# AT32UC3L0256 device description
Architecture: AVR32_UC3; Family: AVR UC3
Registers are 32-bit, read-write, reset 0x0 unless marked. A register's access mark holds for its fields unless they carry their own. Offsets are from the block's base; [hi:lo] are bit positions; lines under a group give offsets from that group; {n}, {i} and the like mark numbered series; 'fields as' and 'values as' point back to an identical list.

## TWIS — Two-wire Slave Interface
Instances: TWIS0 0xffff4c00, TWIS1 0xffff5000
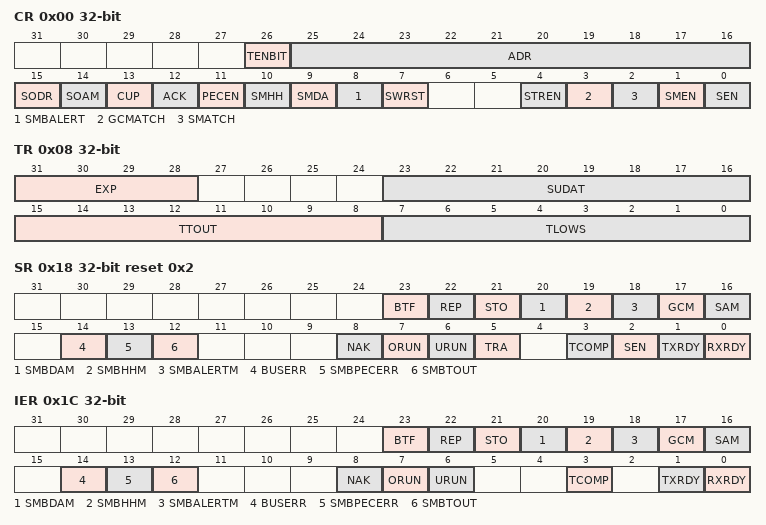
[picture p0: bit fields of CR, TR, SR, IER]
0x00 CR — Control Register
  [26] TENBIT — Ten Bit Address Match
  [25:16] ADR — Slave Address
  [15] SODR — Stretch Clock on Data Byte Reception
  [14] SOAM — Stretch Clock on Address Match
  [13] CUP — NBYTES Count Up
  [12] ACK — Slave Receiver Data Phase ACK Value
  [11] PECEN — Packet Error Checking Enable
  [10] SMHH — SMBus Host Header
  [9] SMDA — SMBus Default Address
  [8] SMBALERT — SMBus Alert
  [7] SWRST — Software Reset
  [4] STREN — Clock Stretch Enable
  [3] GCMATCH — General Call Address Match
  [2] SMATCH — Slave Address Match
  [1] SMEN — SMBus Mode Enable
  [0] SEN — Slave Enable
0x04 NBYTES
  [7:0] NBYTES — Number of Bytes to Transfer
0x08 TR — Timing Register
  [31:28] EXP — Clock Prescaler
  [23:16] SUDAT — Data Setup Cycles
  [15:8] TTOUT — SMBus Ttimeout Cycles
  [7:0] TLOWS — SMBus Tlow:sext Cycles
0x0C RHR ro — Receive Holding Register
  [7:0] RXDATA — Received Data Byte
0x10 THR wo — Transmit Holding Register
  [7:0] TXDATA — Data Byte to Transmit
0x14 PECR ro — Packet Error Check Register
  [7:0] PEC — Calculated PEC Value
0x18 SR ro reset 0x2 — Status Register
  [23] BTF — Byte Transfer Finished
  [22] REP — Repeated Start Received
  [21] STO — Stop Received
  [20] SMBDAM — SMBus Default Address Match
  [19] SMBHHM — SMBus Host Header Address Match
  [18] SMBALERTM — SMBus Alert Response Address Match
  [17] GCM — General Call Match
  [16] SAM — Slave Address Match
  [14] BUSERR — Bus Error
  [13] SMBPECERR — SMBus PEC Error
  [12] SMBTOUT — SMBus Timeout
  [8] NAK — NAK Received
  [7] ORUN — Overrun
  [6] URUN — Underrun
  [5] TRA — Transmitter Mode
  [3] TCOMP — Transmission Complete
  [2] SEN — Slave Enabled
  [1] TXRDY — TX Buffer Ready
  [0] RXRDY — RX Buffer Ready
0x1C IER wo — Interrupt Enable Register
  [23] BTF — Byte Transfer Finished
  [22] REP — Repeated Start Received
  [21] STO — Stop Received
  [20] SMBDAM — SMBus Default Address Match
  [19] SMBHHM — SMBus Host Header Address Match
  [18] SMBALERTM — SMBus Alert Response Address Match
  [17] GCM — General Call Match
  [16] SAM — Slave Address Match
  [14] BUSERR — Bus Error
  [13] SMBPECERR — SMBus PEC Error
  [12] SMBTOUT — SMBus Timeout
  [8] NAK — NAK Received
  [7] ORUN — Overrun
  [6] URUN — Underrun
  [3] TCOMP — Transmission Complete
  [1] TXRDY — TX Buffer Ready
  [0] RXRDY — RX Buffer Ready
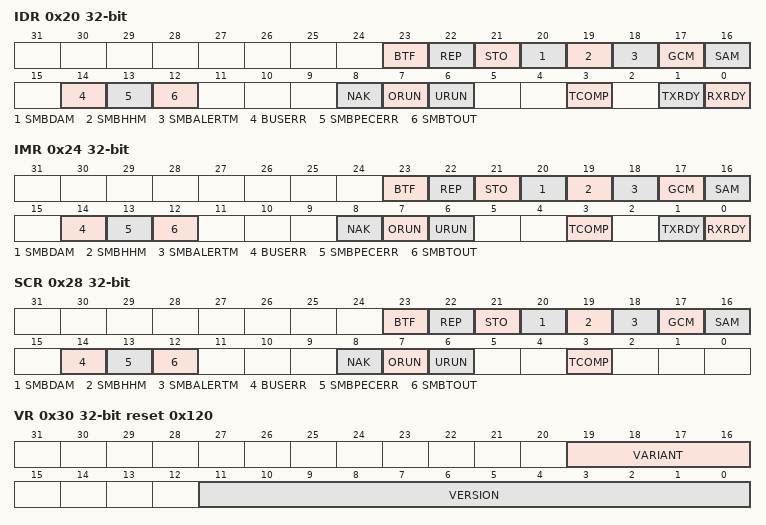
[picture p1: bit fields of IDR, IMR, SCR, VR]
0x20 IDR wo — Interrupt Disable Register
  fields as IER
0x24 IMR ro — Interrupt Mask Register
  fields as IER
0x28 SCR wo — Status Clear Register
  [23] BTF — Byte Transfer Finished
  [22] REP — Repeated Start Received
  [21] STO — Stop Received
  [20] SMBDAM — SMBus Default Address Match
  [19] SMBHHM — SMBus Host Header Address Match
  [18] SMBALERTM — SMBus Alert Response Address Match
  [17] GCM — General Call Match
  [16] SAM — Slave Address Match
  [14] BUSERR — Bus Error
  [13] SMBPECERR — SMBus PEC Error
  [12] SMBTOUT — SMBus Timeout
  [8] NAK — NAK Received
  [7] ORUN — Overrun
  [6] URUN — Underrun
  [3] TCOMP — Transmission Complete
0x2C PR ro — Parameter Register
0x30 VR ro reset 0x120 — Version Register
  [19:16] VARIANT — Variant Number
  [11:0] VERSION — Version Number

## WDT — Watchdog Timer
Instances: WDT 0xffff2000
Parameters: WDT_KEY_CONST=85
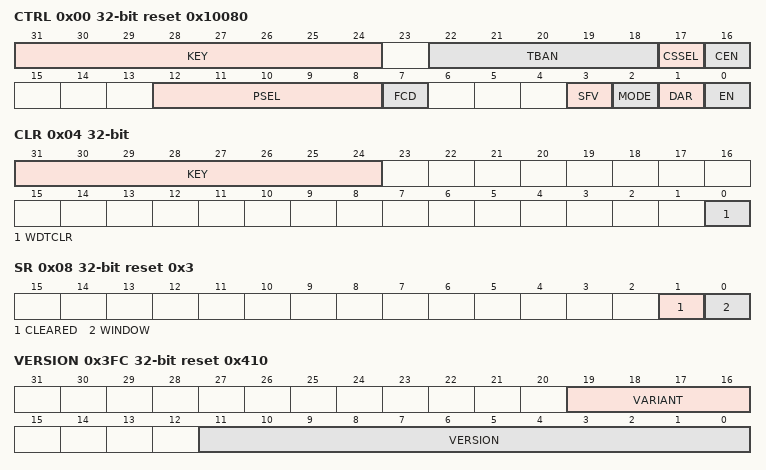
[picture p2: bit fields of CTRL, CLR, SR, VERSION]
0x00 CTRL reset 0x10080 — Control Register
  [31:24] KEY
  [22:18] TBAN — TBAN Prescale Select
  [17] CSSEL — Clock Source Selection
  [16] CEN — Clock Enable
  [12:8] PSEL — Timeout Prescale Select
  [7] FCD — WDT Fuse Calibration Done
  [3] SFV — WDT Store Final Value
  [2] MODE — WDT Mode
  [1] DAR — WDT Disable After Reset
  [0] EN — WDT Enable
0x04 CLR wo — Clear Register
  [31:24] KEY
  [0] WDTCLR — Clear WDT counter
0x08 SR ro reset 0x3 — Status Register
  [1] CLEARED — WDT cleared
  [0] WINDOW — WDT in window
0x3FC VERSION ro reset 0x410
  [19:16] VARIANT — Variant number
  [11:0] VERSION — Version number

## GPIO_LOCAL — Local Bus Mapped GPIO Registers
Instances: GPIO_LOCAL 0x40000000
Parameters: PORT_LENGTH=AVR32_GPIO_PORT_LENGTH
{0x0+0x100*i} port[{i}] (i=0..63) group
  0x40 ODERW wo reset not defined — Output Driver Enable Register - Write
  0x44 ODERS wo reset not defined — Output Driver Enable Register - Set
  0x48 ODERC wo reset not defined — Output Driver Enable Register - Clear
  0x4C ODERT wo reset not defined — Output Driver Enable Register - Toggle
  0x50 OVRW wo reset not defined — Output Value Register - Write
  0x54 OVRS wo reset not defined — Output Value Register - Set
  0x58 OVRC wo reset not defined — Output Value Register - Clear
  0x5C OVRT wo reset not defined — Output Value Register - Toggle
  0x60 PVR ro reset not defined — Pin Value Register
